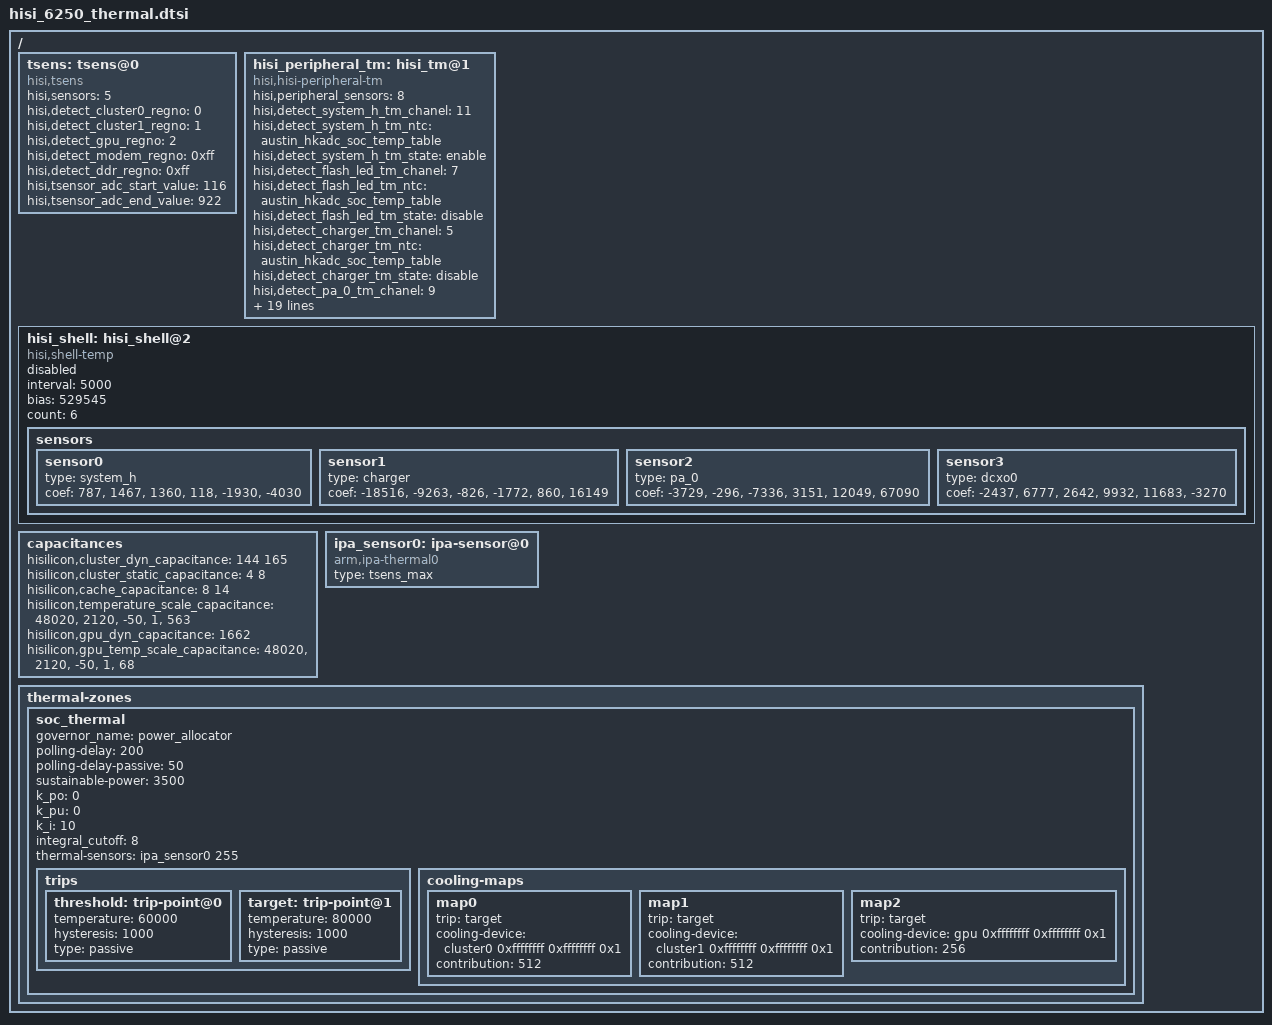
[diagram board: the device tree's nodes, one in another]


  /{

		tsens: tsens@0{
			compatible = "hisi,tsens";
			hisi,sensors = <5>;
			hisi,detect_cluster0_regno = <0>;
			hisi,detect_cluster1_regno = <1>;
			hisi,detect_gpu_regno = <2>;
			hisi,detect_modem_regno = <0xff>;
			hisi,detect_ddr_regno = <0xff>;

			hisi,tsensor_adc_start_value = <116>;
			hisi,tsensor_adc_end_value = <922>;
		};

		hisi_peripheral_tm: hisi_tm@1 {
			compatible = "hisi,hisi-peripheral-tm";
			hisi,peripheral_sensors = <8>;

			hisi,detect_system_h_tm_chanel = <11>;
			hisi,detect_system_h_tm_ntc = "austin_hkadc_soc_temp_table";
			hisi,detect_system_h_tm_state = "enable";

			hisi,detect_flash_led_tm_chanel = <7>;
			hisi,detect_flash_led_tm_ntc = "austin_hkadc_soc_temp_table";
			hisi,detect_flash_led_tm_state = "disable";

			hisi,detect_charger_tm_chanel = <5>;
			hisi,detect_charger_tm_ntc = "austin_hkadc_soc_temp_table";
			hisi,detect_charger_tm_state = "disable";

			hisi,detect_pa_0_tm_chanel = <9>;
			hisi,detect_pa_0_tm_ntc = "austin_hkadc_pa_temp_table";
			hisi,detect_pa_0_tm_state = "enable";

			hisi,detect_pa_1_tm_chanel = <12>;
			hisi,detect_pa_1_tm_ntc = "austin_hkadc_pa_temp_table";
			hisi,detect_pa_1_tm_state = "disable";

			hisi,detect_dcxo0_tm_chanel = <3>;
			hisi,detect_dcxo0_tm_ntc = "austin_hkadc_adc_temp_table";
			hisi,detect_dcxo0_tm_state = "enable";

			hisi,detect_shell_tm_chanel = <7>;
			hisi,detect_shell_tm_ntc = "austin_hkadc_soc_temp_table";
			hisi,detect_shell_tm_state = "disable";

			hisi,detect_charger1_tm_chanel = <4>;
			hisi,detect_charger1_tm_ntc = "austin_hkadc_soc_temp_table";
			hisi,detect_charger1_tm_state = "disable";
		};

		hisi_shell: hisi_shell@2 {
			compatible = "hisi,shell-temp";
			interval = <5000>;
			bias = <529545>;
			count = <6>;
			status = "disabled";
			sensors {
				sensor0 {
					type = "system_h";
					coef = "787","1467","1360","118","-1930","-4030";
				};
				sensor1 {
					type = "charger";
					coef = "-18516","-9263","-826","-1772","860","16149";
				};
				sensor2 {
					type = "pa_0";
					coef = "-3729","-296","-7336","3151","12049","67090";
				};
				sensor3 {
					type = "dcxo0";
					coef = "-2437","6777","2642","9932","11683","-3270";
				};
			};
		};

		capacitances {
			hisilicon,cluster_dyn_capacitance  = <144 165>;/*little big*/
			hisilicon,cluster_static_capacitance = <4 8>;/*little big*/
			hisilicon,cache_capacitance  = <8 14>;/*little big*/
			hisilicon,temperature_scale_capacitance = "48020","2120","-50","1","563"; /*temperature_scale_capacitance*/
			hisilicon,gpu_dyn_capacitance  = <1662>;
			hisilicon,gpu_temp_scale_capacitance = "48020","2120","-50","1","68";
		};

		ipa_sensor0: ipa-sensor@0 {
			type = "tsens_max";
			compatible = "arm,ipa-thermal0";
			#thermal-sensor-cells = <1>;
			status = "ok";
		};

		thermal-zones {
			soc_thermal {
				governor_name = "power_allocator";
				polling-delay = <200>;
				polling-delay-passive = <50>;
				sustainable-power = <3500>;
				k_po = <0>;
				k_pu = <0>;
				k_i = <10>;
				integral_cutoff = <8>;
				thermal-sensors = <&ipa_sensor0 255>;

				trips {
				         threshold: trip-point@0 {
				                    temperature = <60000>;
				                    hysteresis = <1000>;
				                    type = "passive";
				        };
				        target: trip-point@1 {
				                   temperature = <80000>;
				                   hysteresis = <1000>;
				                   type = "passive";
				        };
				};

				cooling-maps {
				           map0 {
				                   trip = <&target>;
				                   cooling-device = <&cluster0 0xffffffff 0xffffffff 0x1>;
				                   contribution = <512>;
				           };
				           map1 {
				                   trip = <&target>;
				                   cooling-device = <&cluster1 0xffffffff 0xffffffff 0x1>;
				                   contribution = <512>;
				           };
				           map2 {
				                   trip = <&target>;
				                   cooling-device = <&gpu 0xffffffff 0xffffffff 0x1>;
				                   contribution = <256>;
				           };
				};

			};
		};

	};

